AUTOSAR XML (schema 00046)
package /ComponentTypes
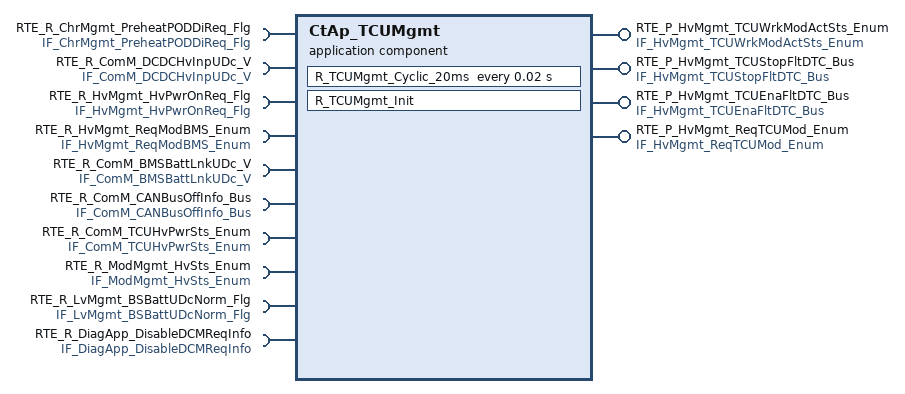
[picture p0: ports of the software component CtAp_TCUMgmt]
  application sw component type CtAp_TCUMgmt
    provide port RTE_P_HvMgmt_TCUWrkModActSts_Enum: nonqueued-sender-com-spec{data-element=tec_HvMgmt_TCUWrkModActSts_Enum, init-value=0}, provided-interface=IF_HvMgmt_TCUWrkModActSts_Enum
    provide port RTE_P_HvMgmt_TCUStopFltDTC_Bus: nonqueued-sender-com-spec{data-element=tec_HvMgmt_TCUStopFltDTC_Bus, init-value=fields=[HvMgmt_MonStatTCUStopFltDTC:0, HvMgmt_MonResTCUStopFltDTC:0, HvMgmt_ErrStatTCUStopFltDTC:0, HvMgmt_ErrResTCUStopFltDTC:0]}, provided-interface=IF_HvMgmt_TCUStopFltDTC_Bus
    provide port RTE_P_HvMgmt_TCUEnaFltDTC_Bus: nonqueued-sender-com-spec{data-element=tec_HvMgmt_TCUEnaFltDTC_Bus, init-value=fields=[HvMgmt_MonStatTCUEnaFltDTC:0, HvMgmt_MonResTCUEnaFltDTC:0, HvMgmt_ErrStatTCUEnaFltDTC:0, HvMgmt_ErrResTCUEnaFltDTC:0]}, provided-interface=IF_HvMgmt_TCUEnaFltDTC_Bus
    9 x require port:
      RTE_R_ChrMgmt_PreheatPODDiReq_Flg: nonqueued-receiver-com-spec{data-element=tec_ChrMgmt_PreheatPODDiReq_Flg, filter=data-filter-type=ALWAYS, init-value=0}, required-interface=IF_ChrMgmt_PreheatPODDiReq_Flg
      RTE_R_ComM_DCDCHvInpUDc_V: nonqueued-receiver-com-spec{data-element=tec_ComM_DCDCHvInpUDc_V, filter=data-filter-type=ALWAYS, init-value=0}, required-interface=IF_ComM_DCDCHvInpUDc_V
      RTE_R_HvMgmt_HvPwrOnReq_Flg: nonqueued-receiver-com-spec{data-element=tec_HvMgmt_HvPwrOnReq_Flg, filter=data-filter-type=ALWAYS, init-value=0}, required-interface=IF_HvMgmt_HvPwrOnReq_Flg
      RTE_R_HvMgmt_ReqModBMS_Enum: nonqueued-receiver-com-spec{data-element=tec_HvMgmt_ReqModBMS_Enum, filter=data-filter-type=ALWAYS, init-value=0}, required-interface=IF_HvMgmt_ReqModBMS_Enum
      RTE_R_ComM_BMSBattLnkUDc_V: nonqueued-receiver-com-spec{data-element=tec_ComM_BMSBattLnkUDc_V, filter=data-filter-type=ALWAYS, init-value=0}, required-interface=IF_ComM_BMSBattLnkUDc_V
      RTE_R_ComM_CANBusOffInfo_Bus: required-interface=IF_ComM_CANBusOffInfo_Bus
        required-com-specs:
          data-element=tec_ComM_EPTCANBusOffInfo_Bus, filter=data-filter-type=ALWAYS, init-value=fields=[ComM_MonStatEPTCANBusOffInfo:0, ComM_MonResEPTCANBusOffInfo:0, ComM_ErrStatEPTCANBusOffInfo:0, ComM_ErrResEPTCANBusOffInfo:0]
          data-element=tec_ComM_CHCANBusOffInfo_Bus, filter=data-filter-type=ALWAYS, init-value=fields=[ComM_MonStatCHCANBusOffInfo:0, ComM_MonResCHCANBusOffInfo:0, ComM_ErrStatCHCANBusOffInfo:0, ComM_ErrResCHCANBusOffInfo:0]
          data-element=tec_ComM_EPTCANBusOffDTCInfo_Bus, filter=data-filter-type=ALWAYS, init-value=fields=[ComM_MonStatEPTCANBusOffDTCInfo:0, ComM_MonResEPTCANBusOffDTCInfo:0, ComM_ErrStatEPTCANBusOffDTCInfo:0, ComM_ErrResEPTCANBusOffDTCInfo:0]
          data-element=tec_ComM_CHCANBusOffDTCInfo_Bus, filter=data-filter-type=ALWAYS, init-value=fields=[ComM_MonStatCHCANBusOffDTCInfo:0, ComM_MonResCHCANBusOffDTCInfo:0, ComM_ErrStatCHCANBusOffDTCInfo:0, ComM_ErrResCHCANBusOffDTCInfo:0]
          data-element=tec_ComM_DCCANBusOffDTCInfo_Bus, init-value=fields=[ComM_MonStatDCCANDTCBusOffInfo:0, ComM_MonResDCCANDTCBusOffInfo:0, ComM_ErrStatDCCANDTCBusOffInfo:0, ComM_ErrResDCCANDTCBusOffInfo:0]
          data-element=tec_ComM_DCCANBusOffInfo_Bus, init-value=fields=[ComM_MonStatDCCANBusOffInfo:0, ComM_MonResDCCANBusOffInfo:0, ComM_ErrStatDCCANBusOffInfo:0, ComM_ErrResDCCANBusOffInfo:0]
      RTE_R_ComM_TCUHvPwrSts_Enum: nonqueued-receiver-com-spec{data-element=tec_ComM_TCUHvPwrSts_Enum, filter=data-filter-type=ALWAYS, init-value=0}, required-interface=IF_ComM_TCUHvPwrSts_Enum
      RTE_R_ModMgmt_HvSts_Enum: nonqueued-receiver-com-spec{data-element=tec_ModMgmt_HvSts_Enum, filter=data-filter-type=ALWAYS, init-value=0}, required-interface=IF_ModMgmt_HvSts_Enum
      RTE_R_LvMgmt_BSBattUDcNorm_Flg: nonqueued-receiver-com-spec{data-element=tec_LvMgmt_BSBattUDcNorm_Flg, filter=data-filter-type=ALWAYS, init-value=0}, required-interface=IF_LvMgmt_BSBattUDcNorm_Flg
    provide port RTE_P_HvMgmt_ReqTCUMod_Enum: nonqueued-sender-com-spec{data-element=tec_HvMgmt_ReqTCUMod_Enum, init-value=0}, provided-interface=IF_HvMgmt_ReqTCUMod_Enum
    require port RTE_R_DiagApp_DisableDCMReqInfo: nonqueued-receiver-com-spec{data-element=tec_DiagApp_DisableDCMReqInfo, filter=data-filter-type=ALWAYS, init-value=0}, required-interface=IF_DiagApp_DisableDCMReqInfo
    behavior CtAp_TCUMgmt_InternalBehavior
      timing event TMT_R_TCUMgmt_Cyclic_20ms: start-on-event=R_TCUMgmt_Cyclic_20ms, period=0.02
      init event CtAp_TCUMgmt_InitEvent: start-on-event=R_TCUMgmt_Init
      runnable R_TCUMgmt_Cyclic_20ms
        data-receive-point-by-arguments:
          10 x access:
            REC_RTE_R_ChrMgmt_PreheatPODDiReq_Flg_tec_ChrMgmt_PreheatPODDiReq_Flg: accessed-variable=RTE_R_ChrMgmt_PreheatPODDiReq_Flg.tec_ChrMgmt_PreheatPODDiReq_Flg
            REC_RTE_R_ComM_BMSBattLnkUDc_V_tec_ComM_BMSBattLnkUDc_V: accessed-variable=RTE_R_ComM_BMSBattLnkUDc_V.tec_ComM_BMSBattLnkUDc_V
            REC_RTE_R_ComM_CANBusOffInfo_Bus_tec_ComM_EPTCANBusOffInfo_Bus: accessed-variable=RTE_R_ComM_CANBusOffInfo_Bus.tec_ComM_EPTCANBusOffInfo_Bus
            REC_RTE_R_ComM_DCDCHvInpUDc_V_tec_ComM_DCDCHvInpUDc_V: accessed-variable=RTE_R_ComM_DCDCHvInpUDc_V.tec_ComM_DCDCHvInpUDc_V
            REC_RTE_R_ComM_TCUHvPwrSts_Enum_tec_ComM_TCUHvPwrSts_Enum: accessed-variable=RTE_R_ComM_TCUHvPwrSts_Enum.tec_ComM_TCUHvPwrSts_Enum
            REC_RTE_R_HvMgmt_HvPwrOnReq_Flg_tec_HvMgmt_HvPwrOnReq_Flg: accessed-variable=RTE_R_HvMgmt_HvPwrOnReq_Flg.tec_HvMgmt_HvPwrOnReq_Flg
            REC_RTE_R_HvMgmt_ReqModBMS_Enum_tec_HvMgmt_ReqModBMS_Enum: accessed-variable=RTE_R_HvMgmt_ReqModBMS_Enum.tec_HvMgmt_ReqModBMS_Enum
            REC_RTE_R_LvMgmt_BSBattUDcNorm_Flg_tec_LvMgmt_BSBattUDcNorm_Flg: accessed-variable=RTE_R_LvMgmt_BSBattUDcNorm_Flg.tec_LvMgmt_BSBattUDcNorm_Flg
            REC_RTE_R_ModMgmt_HvSts_Enum_tec_ModMgmt_HvSts_Enum: accessed-variable=RTE_R_ModMgmt_HvSts_Enum.tec_ModMgmt_HvSts_Enum
            REC_RTE_R_DiagApp_DisableDCMReqInfo_tec_DiagApp_DisableDCMReqInfo: accessed-variable=RTE_R_DiagApp_DisableDCMReqInfo.tec_DiagApp_DisableDCMReqInfo
        data-send-points:
          4 x access:
            SEND_RTE_P_HvMgmt_ReqTCUMod_Enum_tec_HvMgmt_ReqTCUMod_Enum: accessed-variable=RTE_P_HvMgmt_ReqTCUMod_Enum.tec_HvMgmt_ReqTCUMod_Enum
            SEND_RTE_P_HvMgmt_TCUEnaFltDTC_Bus_tec_HvMgmt_TCUEnaFltDTC_Bus: accessed-variable=RTE_P_HvMgmt_TCUEnaFltDTC_Bus.tec_HvMgmt_TCUEnaFltDTC_Bus
            SEND_RTE_P_HvMgmt_TCUStopFltDTC_Bus_tec_HvMgmt_TCUStopFltDTC_Bus: accessed-variable=RTE_P_HvMgmt_TCUStopFltDTC_Bus.tec_HvMgmt_TCUStopFltDTC_Bus
            SEND_RTE_P_HvMgmt_TCUWrkModActSts_Enum_tec_HvMgmt_TCUWrkModActSts_Enum: accessed-variable=RTE_P_HvMgmt_TCUWrkModActSts_Enum.tec_HvMgmt_TCUWrkModActSts_Enum
      runnable R_TCUMgmt_Init
  swc implementation CtAp_TCUMgmt_Implementation: behavior=CtAp_TCUMgmt_InternalBehavior
